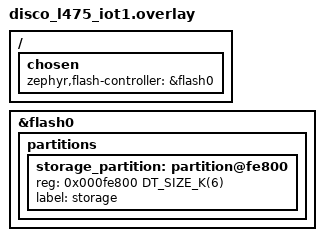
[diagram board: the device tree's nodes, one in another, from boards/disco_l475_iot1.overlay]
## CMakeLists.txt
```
# SPDX-License-Identifier: Apache-2.0

cmake_minimum_required(VERSION 3.28.0)

macro(app_set_runner_args)
  board_runner_args(dfu-util "--dfuse-modifiers=force:mass-erase")
  board_runner_args(pyocd "--erase")
  board_runner_args(nrfjprog "--erase")
endmacro()

find_package(Zephyr REQUIRED HINTS $ENV{ZEPHYR_BASE})
project(nvs)


target_sources(app PRIVATE src/main.c)
target_include_directories(app PRIVATE ${ZEPHYR_BASE}/subsys/kvss/nvs)
```

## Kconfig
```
# Copyright 2025 NXP
# SPDX-License-Identifier: Apache-2.0

mainmenu "NVS Sample Configuration"

config NVS_SAMPLE_MAX_REBOOT
	int "Maximum reboot counter value"
	default 5
	range 1 1000
	help
	  Maximum number of reboots to perform before resetting the counter.

config NVS_SAMPLE_REBOOT_COUNTDOWN
	int "Reboot countdown value (in iterations)"
	default 5
	range 1 60
	help
	  Number of countdown iterations to wait before rebooting the device.
	  Each iteration takes NVS_SAMPLE_SLEEP_TIME milliseconds.

config NVS_SAMPLE_SLEEP_TIME
	int "Sleep time between reboot countdown iterations (in milliseconds)"
	default 100
	range 10 10000
	help
	  Duration in milliseconds to sleep between reboot countdown iterations.

source "Kconfig.zephyr"
```

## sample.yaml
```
sample:
  name: NVS Sample

tests:
  sample.nvs.basic:
    tags: nvs
    depends_on: nvs
    platform_exclude: qemu_x86
    integration_platforms:
      - nrf52dk/nrf52832
    harness: console
    harness_config:
      type: multi_line
      regex:
        - "Id: 1, Address: 192.168.1.1"
        - "Id: 2, Key: ff fe fd fc fb fa f9 f8"
        - "Id: 3, Reboot_counter: (.*)"
        - "Id: 4, Data: DATA"
        - "Id: 5, Longarray: 0 1 2 3 4 5 6 7 8 9 a b c d e f 10 11 12 13 14 15 16 17 18 19 1a 1b \
           1c 1d 1e 1f 20 21 22 23 24 25 26 27 28 29 2a 2b 2c 2d 2e 2f 30 31 32 33 34 35 36 37 38 \
           39 3a 3b 3c 3d 3e 3f 40 41 42 43 44 45 46 47 48 49 4a 4b 4c 4d 4e 4f 50 51 52 53 54 55 \
           56 57 58 59 5a 5b 5c 5d 5e 5f 60 61 62 63 64 65 66 67 68 69 6a 6b 6c 6d 6e 6f 70 71 72 \
           73 74 75 76 77 78 79 7a 7b 7c 7d 7e 7f"
  sample.nvs.internal_flash:
    tags: nvs
    depends_on: nvs
    integration_platforms:
      - frdm_mcxn947/mcxn947/cpu0
    platform_allow:
      - frdm_mcxn947/mcxn947/cpu0
      - mcx_n9xx_evk/mcxn947/cpu0
    extra_args:
      - platform:frdm_mcxn947/mcxn947/cpu0:"DTC_OVERLAY_FILE=nxp/mcxn947_internal_flash.overlay"
      - platform:mcx_n9xx_evk/mcxn947/cpu0:"DTC_OVERLAY_FILE=nxp/mcxn947_internal_flash.overlay"
    harness: console
    harness_config:
      type: multi_line
      regex:
        - "Id: 1, Address: 192.168.1.1"
        - "Id: 2, Key: ff fe fd fc fb fa f9 f8"
        - "Id: 3, Reboot_counter: (.*)"
        - "Id: 4, Data: DATA"
        - "Id: 5, Longarray: 0 1 2 3 4 5 6 7 8 9 a b c d e f 10 11 12 13 14 15 16 17 18 19 1a 1b \
           1c 1d 1e 1f 20 21 22 23 24 25 26 27 28 29 2a 2b 2c 2d 2e 2f 30 31 32 33 34 35 36 37 38 \
           39 3a 3b 3c 3d 3e 3f 40 41 42 43 44 45 46 47 48 49 4a 4b 4c 4d 4e 4f 50 51 52 53 54 55 \
           56 57 58 59 5a 5b 5c 5d 5e 5f 60 61 62 63 64 65 66 67 68 69 6a 6b 6c 6d 6e 6f 70 71 72 \
           73 74 75 76 77 78 79 7a 7b 7c 7d 7e 7f"
```

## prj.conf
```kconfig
CONFIG_FLASH=y

CONFIG_NVS=y
CONFIG_LOG=y
CONFIG_LOG_MODE_IMMEDIATE=y
CONFIG_NVS_LOG_LEVEL_DBG=y
CONFIG_REBOOT=y
CONFIG_MPU_ALLOW_FLASH_WRITE=y
CONFIG_MAIN_STACK_SIZE=2048
```

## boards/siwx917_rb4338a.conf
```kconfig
CONFIG_SYSTEM_WORKQUEUE_STACK_SIZE=4096
CONFIG_MAIN_STACK_SIZE=4096
CONFIG_NVS_INIT_BAD_MEMORY_REGION=y
```

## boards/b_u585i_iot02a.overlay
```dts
/*
 * Copyright (c) 2024 STMicroelectronics
 *
 * SPDX-License-Identifier: Apache-2.0
 */

&mx25lm51245 {
	status = "disabled";
};
```

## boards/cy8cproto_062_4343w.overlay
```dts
/*
 * SPDX-FileCopyrightText: Copyright (c) 2026 Infineon Technologies AG,
 * SPDX-FileCopyrightText: or an affiliate of Infineon Technologies AG. All rights reserved.
 *
 * SPDX-License-Identifier: Apache-2.0
 */

&flash0 {
	partitions {
		compatible = "fixed-partitions";
		#address-cells = <1>;
		#size-cells = <1>;

		/* Set 3Kb of storage at the end of the of 2Mb flash 0 */
		storage_partition: partition@1ff400 {
			reg = <0x1ff400 DT_SIZE_K(3)>;
			label = "storage";
		};
	};
};
```

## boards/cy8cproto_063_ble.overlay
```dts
/*
 * SPDX-FileCopyrightText: Copyright (c) 2026 Infineon Technologies AG,
 * SPDX-FileCopyrightText: or an affiliate of Infineon Technologies AG. All rights reserved.
 *
 * SPDX-License-Identifier: Apache-2.0
 */

&flash0 {
	partitions {
		compatible = "fixed-partitions";
		#address-cells = <1>;
		#size-cells = <1>;

		/* Set 3Kb of storage at the end of the of 1Mb flash 0 */
		storage_partition: partition@ff400 {
			reg = <0xff400 DT_SIZE_K(3)>;
			label = "storage";
		};
	};
};
```

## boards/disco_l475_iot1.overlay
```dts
/*
 * Copyright (c) 2022 STMicroelectronics
 *
 * SPDX-License-Identifier: Apache-2.0
 */

/delete-node/ &storage_partition;

/ {
	chosen {
		zephyr,flash-controller = &flash0;
	};
};

&flash0 {
	partitions {
		/* Set 6Kb of storage at the end of the 1Mb of flash */
		storage_partition: partition@fe800 {
			reg = <0x000fe800 DT_SIZE_K(6)>;
			label = "storage";
		};
	};
};
```

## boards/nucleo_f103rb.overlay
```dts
/*
 * Copyright (c) 2022 STMicroelectronics
 *
 * SPDX-License-Identifier: Apache-2.0
 */

/delete-node/ &storage_partition;

&flash0 {
	partitions {
		/* Set 3KB of storage at the end of 128KB flash */
		storage_partition: partition@1f400 {
			reg = <0x0001f400 DT_SIZE_K(3)>;
			label = "storage";
		};
	};
};
```

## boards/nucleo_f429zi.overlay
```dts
/*
 * Copyright (c) 2022 STMicroelectronics
 *
 * SPDX-License-Identifier: Apache-2.0
 */

&flash0 {
	partitions {
		/* Set 48KB of storage at the beginning of bank2 in order to have 3 sectors smaller than 32K
		 * 	(nvs.h: uint16_t sector_size)
		 */
		storage_partition: partition@100000 {
			reg = <0x000100000 DT_SIZE_K(48)>;
			label = "storage";
		};
	};
};
```

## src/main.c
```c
/*
 * NVS Sample for Zephyr using high level API, the sample illustrates the usage
 * of NVS for storing data of different kind (strings, binary blobs, unsigned
 * 32 bit integer) and also how to read them back from flash. The reading of
 * data is illustrated for both a basic read (latest added value) as well as
 * reading back the history of data (previously added values). Next to reading
 * and writing data it also shows how data can be deleted from flash.
 *
 * The sample stores the following items:
 * 1. A string representing an IP-address: stored at id=1, data="192.168.1.1"
 * 2. A binary blob representing a key: stored at id=2, data=FF FE FD FC FB FA
 *    F9 F8
 * 3. A reboot counter (32bit): stored at id=3, data=reboot_counter
 * 4. A string: stored at id=4, data="DATA" (used to illustrate deletion of
 * items)
 *
 * At first boot the sample checks if the data is available in flash and adds
 * the items if they are not in flash.
 *
 * Every reboot increases the values of the reboot_counter and updates it in
 * flash.
 *
 * At the 10th reboot the string item with id=4 is deleted (or marked for
 * deletion).
 *
 * At the 11th reboot the string item with id=4 can no longer be read with the
 * basic nvs_read() function as it has been deleted. It is possible to read the
 * value with nvs_read_hist()
 *
 * At the 78th reboot the first sector is full and a new sector is taken into
 * use. The data with id=1, id=2 and id=3 is copied to the new sector. As a
 * result of this the history of the reboot_counter will be removed but the
 * latest values of address, key and reboot_counter is kept.
 *
 * Copyright (c) 2018 Laczen
 *
 * SPDX-License-Identifier: Apache-2.0
 */


#include <zephyr/kernel.h>
#include <zephyr/sys/reboot.h>
#include <zephyr/device.h>
#include <string.h>
#include <zephyr/drivers/flash.h>
#include <zephyr/storage/flash_map.h>
#include <zephyr/kvss/nvs.h>

static struct nvs_fs fs;

#define NVS_PARTITION		storage_partition
#define NVS_PARTITION_DEVICE	PARTITION_DEVICE(NVS_PARTITION)
#define NVS_PARTITION_OFFSET	PARTITION_OFFSET(NVS_PARTITION)

#define ADDRESS_ID 1
#define KEY_ID 2
#define RBT_CNT_ID 3
#define STRING_ID 4
#define LONG_ID 5


int main(void)
{
	int rc = 0, cnt = 0, cnt_his = 0;
	char buf[16];
	uint8_t key[8], longarray[128];
	uint32_t reboot_counter = 0U, reboot_counter_his;
	struct flash_pages_info info;

	/* define the nvs file system by settings with:
	 *	sector_size equal to the pagesize,
	 *	3 sectors
	 *	starting at NVS_PARTITION_OFFSET
	 */
	fs.flash_device = NVS_PARTITION_DEVICE;
	if (!device_is_ready(fs.flash_device)) {
		printk("Flash device %s is not ready\n", fs.flash_device->name);
		return 0;
	}
	fs.offset = NVS_PARTITION_OFFSET;
	rc = flash_get_page_info_by_offs(fs.flash_device, fs.offset, &info);
	if (rc) {
		printk("Unable to get page info, rc=%d\n", rc);
		return 0;
	}
	fs.sector_size = info.size;
	fs.sector_count = 3U;

	rc = nvs_mount(&fs);
	if (rc) {
		printk("Flash Init failed, rc=%d\n", rc);
		return 0;
	}

	/* ADDRESS_ID is used to store an address, lets see if we can
	 * read it from flash, since we don't know the size read the
	 * maximum possible
	 */
	rc = nvs_read(&fs, ADDRESS_ID, &buf, sizeof(buf));
	if (rc > 0) { /* item was found, show it */
		printk("Id: %d, Address: %s\n", ADDRESS_ID, buf);
	} else   {/* item was not found, add it */
		strcpy(buf, "192.168.1.1");
		printk("No address found, adding %s at id %d\n", buf,
		       ADDRESS_ID);
		(void)nvs_write(&fs, ADDRESS_ID, &buf, strlen(buf)+1);
	}
	/* KEY_ID is used to store a key, lets see if we can read it from flash
	 */
	rc = nvs_read(&fs, KEY_ID, &key, sizeof(key));
	if (rc > 0) { /* item was found, show it */
		printk("Id: %d, Key: ", KEY_ID);
		for (int n = 0; n < 8; n++) {
			printk("%x ", key[n]);
		}
		printk("\n");
	} else   {/* item was not found, add it */
		printk("No key found, adding it at id %d\n", KEY_ID);
		key[0] = 0xFF;
		key[1] = 0xFE;
		key[2] = 0xFD;
		key[3] = 0xFC;
		key[4] = 0xFB;
		key[5] = 0xFA;
		key[6] = 0xF9;
		key[7] = 0xF8;
		(void)nvs_write(&fs, KEY_ID, &key, sizeof(key));
	}
	/* RBT_CNT_ID is used to store the reboot counter, lets see
	 * if we can read it from flash
	 */
	rc = nvs_read(&fs, RBT_CNT_ID, &reboot_counter, sizeof(reboot_counter));
	if (rc > 0) { /* item was found, show it */
		printk("Id: %d, Reboot_counter: %d\n",
			RBT_CNT_ID, reboot_counter);
	} else   {/* item was not found, add it */
		printk("No Reboot counter found, adding it at id %d\n",
		       RBT_CNT_ID);
		(void)nvs_write(&fs, RBT_CNT_ID, &reboot_counter,
			  sizeof(reboot_counter));
	}
	/* STRING_ID is used to store data that will be deleted,lets see
	 * if we can read it from flash, since we don't know the size read the
	 * maximum possible
	 */
	rc = nvs_read(&fs, STRING_ID, &buf, sizeof(buf));
	if (rc > 0) {
		/* item was found, show it */
		printk("Id: %d, Data: %s\n",
			STRING_ID, buf);
		/* remove the item if reboot_counter = 10 */
		if (reboot_counter == 10U) {
			(void)nvs_delete(&fs, STRING_ID);
		}
	} else   {
		/* entry was not found, add it if reboot_counter = 0*/
		if (reboot_counter == 0U) {
			printk("Id: %d not found, adding it\n",
			STRING_ID);
			strcpy(buf, "DATA");
			(void)nvs_write(&fs, STRING_ID, &buf, strlen(buf) + 1);
		}
	}

	/* LONG_ID is used to store a larger dataset ,lets see if we can read
	 * it from flash
	 */
	rc = nvs_read(&fs, LONG_ID, &longarray, sizeof(longarray));
	if (rc > 0) {
		/* item was found, show it */
		printk("Id: %d, Longarray: ", LONG_ID);
		for (int n = 0; n < sizeof(longarray); n++) {
			printk("%x ", longarray[n]);
		}
		printk("\n");
	} else   {
		/* entry was not found, add it if reboot_counter = 0*/
		if (reboot_counter == 0U) {
			printk("Longarray not found, adding it as id %d\n",
			       LONG_ID);
			for (int n = 0; n < sizeof(longarray); n++) {
				longarray[n] = n;
			}
			(void)nvs_write(
				&fs, LONG_ID, &longarray, sizeof(longarray));
		}
	}

	cnt = CONFIG_NVS_SAMPLE_REBOOT_COUNTDOWN;
	while (1) {
		k_msleep(CONFIG_NVS_SAMPLE_SLEEP_TIME);
		if (reboot_counter < CONFIG_NVS_SAMPLE_MAX_REBOOT) {
			if (cnt == CONFIG_NVS_SAMPLE_REBOOT_COUNTDOWN) {
				/* print some history information about
				 * the reboot counter
				 * Check the counter history in flash
				 */
				printk("Reboot counter history: ");
				while (1) {
					rc = nvs_read_hist(
						&fs, RBT_CNT_ID,
						&reboot_counter_his,
						sizeof(reboot_counter_his),
						cnt_his);
					if (rc < 0) {
						break;
					}
					printk("...%d", reboot_counter_his);
					cnt_his++;
				}
				if (cnt_his == 0) {
					printk("\n Error, no Reboot counter");
				} else {
					printk("\nOldest reboot counter: %d",
					       reboot_counter_his);
				}
				printk("\nRebooting in ");
			}
			printk("...%d", cnt);
			cnt--;
			if (cnt == 0) {
				printk("\n");
				reboot_counter++;
				(void)nvs_write(
					&fs, RBT_CNT_ID, &reboot_counter,
					sizeof(reboot_counter));
				if (reboot_counter == CONFIG_NVS_SAMPLE_MAX_REBOOT) {
					printk("Doing last reboot...\n");
				}
				sys_reboot(0);
			}
		} else {
			printk("Reboot counter reached max value.\n");
			printk("Reset to 0 and exit test.\n");
			reboot_counter = 0U;
			(void)nvs_write(&fs, RBT_CNT_ID, &reboot_counter,
			  sizeof(reboot_counter));
			break;
		}
	}
	return 0;
}
```
